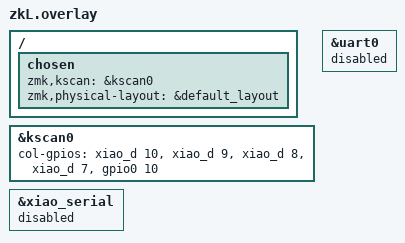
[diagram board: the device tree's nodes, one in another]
#include <dt-bindings/zmk/behaviors.h>
#include <dt-bindings/zmk/keys.h>
#include <dt-bindings/zmk/matrix_transform.h>
#include <physical_layouts.dtsi>
#include "zonkey.dtsi"

/ {
    chosen {
        zmk,kscan = &kscan0;
        zmk,physical-layout = &default_layout;
    };
};

&kscan0 {
    col-gpios
        = <&xiao_d 10 GPIO_ACTIVE_HIGH>
        , <&xiao_d 9 GPIO_ACTIVE_HIGH> 
        , <&xiao_d 8 GPIO_ACTIVE_HIGH> 
        , <&xiao_d 7 GPIO_ACTIVE_HIGH> 
        , <&gpio0 10 GPIO_ACTIVE_HIGH>
        ;
};

&xiao_serial { status = "disabled"; };
&uart0 { status = "disabled"; };
